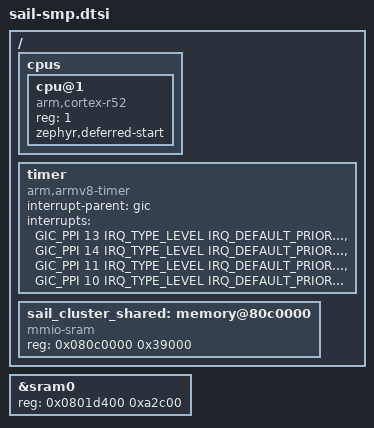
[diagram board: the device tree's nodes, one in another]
/*
 * Copyright The Zephyr Project Contributors
 * SPDX-License-Identifier: Apache-2.0
 */

/*
 * Cluster-0 image with both cores of cluster 0. The second core starts at run
 * time when the fuses do not pair it into lockstep. The SRAM above the image
 * holds the cluster-1 image and the page the two images share.
 */

/ {
	cpus {
		cpu@1 {
			compatible = "arm,cortex-r52";
			reg = <1>;
			device_type = "cpu";
			zephyr,deferred-start;
		};
	};

	timer {
		compatible = "arm,armv8-timer";
		interrupt-parent = <&gic>;
		interrupts = <GIC_PPI 13 IRQ_TYPE_LEVEL IRQ_DEFAULT_PRIORITY>,
			     <GIC_PPI 14 IRQ_TYPE_LEVEL IRQ_DEFAULT_PRIORITY>,
			     <GIC_PPI 11 IRQ_TYPE_LEVEL IRQ_DEFAULT_PRIORITY>,
			     <GIC_PPI 10 IRQ_TYPE_LEVEL IRQ_DEFAULT_PRIORITY>;
	};

	sail_cluster_shared: memory@80c0000 {
		compatible = "mmio-sram";
		reg = <0x080c0000 0x39000>;
	};
};

&sram0 {
	reg = <0x0801d400 0xa2c00>;
};
